# STM32WBA52 register map
File version: 0.1
CPU: CM33 r0p1, little endian, MPU, FPU, 4 interrupt priority bits
Registers are 32-bit, read-write, reset 0x0 unless marked. A register's access mark holds for its fields unless they carry their own. Offsets are from the block's base; [hi:lo] are bit positions; {n}, {i} and the like mark numbered series.

## SAES — Secure AES coprocessor
Base 0x420C0C00
Same registers: SEC_SAES 0x520C0C00
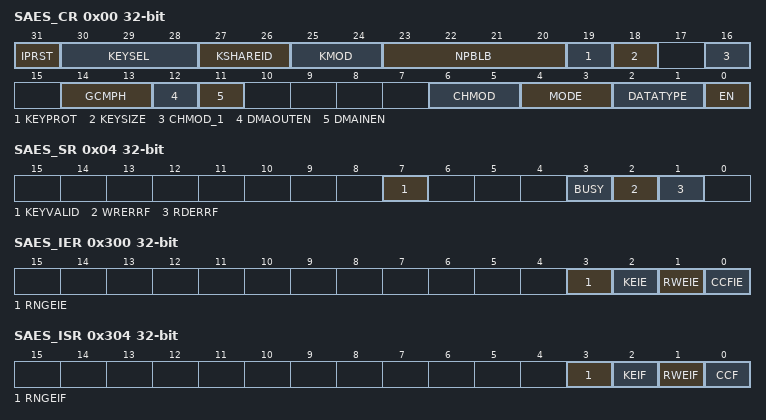
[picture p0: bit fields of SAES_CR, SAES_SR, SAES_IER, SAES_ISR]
0x00 SAES_CR — SAES control register
  [31] IPRST — SAES peripheral software reset Setting the bit resets the SAES peripheral, putting all registers to their default values, except the IPRST bit itself. Hence, any key-relative data are lost. For this reason, it is recommended to set the bit before handing over the SAES to a less secure application. The bit must be low while writing any configuration registers.
  [30:28] KEYSEL — Key selection The bitfield defines the source of the key information to use in the AES cryptographic core. Others: Reserved (if used, unfreeze SAES with IPRST) When KEYSEL[2:0] is different from zero, selected key value is available in key registers when BUSY bit is cleared and KEYVALID is set in the SAES_SR register. Otherwise, the key error flag KEIF is set. Repeated writing of KEYSEL[2:0] with the same non-zero value only triggers the loading of DHUK or BHK when KEYVALID�is cleared. When the application software changes the key selection by writing the KEYSEL[2:0] bitfield, the key registers are immediately erased and the KEYVALID flag cleared. At the end of the decryption process, if KMOD[1:0] is other than zero, KEYSEL[2:0] is cleared. With the bitfield value other than zero and KEYVALID set, the application cannot transfer the ownership of SAES with a loaded key to an application running in another security context (such as secure, non-secure). More specifically, when security of an access to any register does not match the information recorded by SAES, the KEIF flag is set. Attempts to write the bitfield are ignored when the BUSY flag of SAES_SR register is set, as well as when the EN bit of the SAES_CR register is set before the write access and it is not cleared by that write access.
    0=Software key, loaded in key registers SAES_KEYx; 1=Derived hardware unique key (DHUK); 2=Boot hardware key (BHK); 4=XOR of DHUK and BHK; 7=Test mode key (256-bit hardware constant 0xA5A5...A5A5)
  [27:26] KSHAREID — Key share identification This bitfield defines, at the end of a decryption process with KMOD[1:0] at 10 (shared key), which target can read the SAES key registers using a dedicated hardware bus. Others: Reserved Attempts to write the bitfield are ignored when BUSY is set, as well as when EN is set before the write access and it is not cleared by that write access.
    0=AES peripheral
  [25:24] KMOD — Key mode selection The bitfield defines how the SAES key can be used by the application. KEYSIZE must be correctly initialized when setting KMOD[1:0] different from zero. Others: Reserved With KMOD[1:0] other than zero, any attempt to configure the SAES peripheral for use by an application belonging to a different security domain (such as secure or non-secure) results in automatic key erasure and setting of the KEIF flag. Attempts to write the bitfield are ignored when BUSY is set, as well as when EN is set before the write access and it is not cleared by that write access.
    0=Normal key mode. Key registers are freely usable, no specific usage or protection applies to SAES_DINR and SAES_DOUTR registers.; 1=Wrapped key mode. Key loaded in key registers can only be used to encrypt or decrypt AES keys. Hence, when a decryption is selected, read-as-zero SAES_DOUTR register is automatically loaded into SAES key registers after a successful decryption process.; 2=Shared key mode. After a successful decryption process, SAES key registers are shared with the peripheral described in KSHAREID[1:0] bitfield. This sharing is valid only while KMOD[1:0] at 10 and KEYVALID=1. When a decryption is selected, read-as-zero SAES_DOUTR register is automatically loaded into SAES key registers after a successful decryption process.
  [23:20] NPBLB — Number of padding bytes in last block This padding information must be filled by software before processing the last block of GCM payload encryption or CCM payload decryption, otherwise authentication tag computation is incorrect. ...
    0=All bytes are valid (no padding); 1=Padding for the last LSB byte; 15=Padding for the 15 LSB bytes of last block
  [19] KEYPROT — Key protection When set, hardware-based key protection is enabled. Attempts to write the bit are ignored when BUSY is set, as well as when EN is set before the write access and it is not cleared by that write access.
    0=When KEYVALID is set and KEYSEL[2:0]�=�0 application can transfer the ownership of the SAES, with its loaded key, to an application running in another security context (such as non-secure, secure); 1=When KEYVALID is set, key error flag (KEIF) is set when an access to any registers is detected, this access having a security context (for example, secure, non-secure) that does not match the one of the application that loaded the key
  [18] KEYSIZE — Key size selection This bitfield defines the key length in bits of the key used by SAES. When KMOD[1:0] is at 01 or 10, KEYSIZE also defines the length of the key to encrypt or decrypt. Attempts to write the bit are ignored when BUSY is set, as well as when the EN is set before the write access and it is not cleared by that write access.
    0=128-bit; 1=256-bit
  [16] CHMOD_1 — CHMOD[2]
  [14:13] GCMPH — GCM or CCM phase selection This bitfield selects the phase, applicable only with GCM, GMAC or CCM chaining modes. This bitfield has no effect if GCM, GMAC or CCM algorithm is not selected with CHMOD[2:0].
    0=Initialization phase; 1=Header phase; 2=Payload phase; 3=Final phase
  [12] DMAOUTEN — DMA output enable When this bit is set, DMA requests are automatically generated by the peripheral during the output data phase. Setting this bit is ignored when MODE[1:0] is at 01 (key derivation).
    0=DMA for outgoing data transfer is disabled; 1=DMA for outgoing data transfer is enabled
  [11] DMAINEN — DMA input enable When this bit is set, DMA requests are automatically generated by the peripheral during the input data phase. Setting this bit is ignored when MODE[1:0] is at 01 (key derivation).
    0=DMA for incoming data transfer is disabled; 1=DMA for incoming data transfer is enabled
  [6:5] CHMOD — CHMOD[1:0]: Chaining mode This bitfield selects the AES chaining mode: others: Reserved Attempts to write the bitfield are ignored when BUSY is set, as well as when EN is set before the write access and it is not cleared by that write access.
    0=Electronic codebook (ECB); 1=Cipher-block chaining (CBC); 2=Counter mode (CTR); 3=Galois counter mode (GCM) and Galois message authentication code (GMAC); 4=Counter with CBC-MAC (CCM)
  [4:3] MODE — Operating mode This bitfield selects the SAES operating mode: Attempts to write the bitfield are ignored when BUSY is set, as well as when EN is set before the write access and it is not cleared by that write access.
    0=Encryption; 1=Key derivation (or key preparation), for ECB/CBC decryption only; 2=Decryption
  [2:1] DATATYPE — Data type This bitfield defines the format of data written in the SAES_DINR register or read from the SAES_DOUTR register, through selecting the mode of data swapping. This swapping is defined in Section�23.4.17: SAES data registers and data swapping. Attempts to write the bitfield are ignored when BUSY is set, as well as when EN is set before the write access and it is not cleared by that write access.
    0=No swapping (32-bit data); 1=Half-word swapping (16-bit data); 2=Byte swapping (8-bit data); 3=Bit-level swapping
  [0] EN — Enable This bit enables/disables the SAES peripheral. At any moment, clearing then setting the bit re-initializes the SAES peripheral. When KMOD[1:0] is different from 00, using IPRST bit is recommended instead. This bit is automatically cleared by hardware upon the completion of the key preparation (MODE[1:0] at 01) and upon the completion of GCM/GMAC/CCM initialization phase. The bit cannot be set as long as KEYVALID�=�0. The situation is similar for one of the following configurations: 1. KMOD[1:0] at 01 (wrap), CHMOD[2:0] at 11 (GCM) 2. KMOD[1:0] at 01 (wrap), CHMOD[2:0] at 10 (CTR), MODE[1:0] at 00 (encryption).
    0=Disable; 1=Enable
0x04 SAES_SR ro — SAES status register
  [7] KEYVALID — Key valid flag This bit is set by hardware when the key of size defined by KEYSIZE is loaded in SAES_KEYRx key registers. The EN bit can only be set when KEYVALID is set. In normal mode when KEYSEL[2:0] is at 000, the key must be written in the key registers in the correct sequence, otherwise the KEIF flag is set and KEYVALID remains cleared. When KEYSEL[2:0] is different from zero, the BUSY flag is automatically set by SAES. When the key is loaded successfully, BUSY is cleared and KEYVALID set. Upon an error, KEIF is set, BUSY cleared and KEYVALID remains cleared. If set, KEIF must be cleared through the SAES_ICR register, otherwise KEYVALID cannot be set. See the KEIF flag description for more details. For further information on key loading, refer to Section�23.4.18: SAES key registers.
    0=Key not valid; 1=Key valid
  [3] BUSY — Busy This flag indicates whether SAES is idle or busy. SAES is flagged as idle when disabled or when the last processing is completed. SAES is flagged as busy when processing a block data, preparing a key (ECB or CBC decryption only), fetching random number from the RNG, or transferring a shared key to target peripheral. When GCM encryption is selected, this flag must be at zero before suspending current process to manage a higher-priority message. BUSY must also be cleared before selecting the GCM final phase.
    0=Idle; 1=Busy
  [2] WRERRF — Write error flag This bit is set when an unexpected write to the SAES_DINR register occurred. When set WRERRF bit has no impact on the SAES operations. This flag is cleared by setting the RWEIF bit in SAES_ICR register. If RWEIE bit is set in SAES_IER register an interrupt is generated when WRERRF is set. It is cleared by setting the RWEIF bit of the SAES_ICR register.
    0=No error; 1=Unexpected write to SAES_DINR register occurred during computation or data output phase
  [1] RDERRF — Read error flag This bit is set when an unexpected read to the SAES_DOUTR register occurred. When set RDERRF bit has no impact on the SAES operations. This flag is cleared by setting the RWEIF bit in SAES_ICR register. If RWEIE bit is set in SAES_IER register an interrupt is generated when RDERRF is set. It is cleared by setting the RWEIF bit of the SAES_ICR register.
    0=No error; 1=Unexpected read to SAES_DOUTR register occurred during computation or data input phase
0x08 SAES_DINR wo — SAES data input register
  [31:0] DIN — Input data word A four-fold sequential write to this bitfield during the Input phase results in writing a complete 16-bytes block of input data to the SAES peripheral. From the first to the fourth write, the corresponding data weights are [127:96], [95:64], [63:32], and [31:0]. Upon each write, the data from the 32-bit input buffer are handled by the data swap block according to the DATATYPE[1:0] bitfield, then written into the AES core 16-bytes input buffer. Reads return zero.
0x0C SAES_DOUTR ro — SAES data output register
  [31:0] DOUT — Output data word This read-only bitfield fetches a 32-bit output buffer. A four-fold sequential read of this bitfield, upon the computation completion (CCF flag set), virtually reads a complete 16-byte block of output data from the SAES peripheral. Before reaching the output buffer, the data produced by the AES core are handled by the data swap block according to the DATATYPE[1:0] bitfield. Data weights from the first to the fourth read operation are: [127:96], [95:64], [63:32], and [31:0].
0x10 SAES_KEYR0 wo — SAES key register 0
  [31:0] KEY — Cryptographic key, bits [31:0] This write-only bitfield contains the bits [31:0] of the AES encryption or decryption key, depending on the operating mode MODE[1:0] in SAES_CR. The SAES_KEYRx registers may be written only when KEYSIZE value is correct and when the SAES peripheral is disabled (EN bit of the SAES_CR register cleared). A special writing sequence is also required, as described in KEYVALID bit of the SAES_SR register. Note that, if KEYSEL[2:0] is different from 0 and KEYVALID�=�0, the key is directly loaded to SAES_KEYRx registers (hence writes to key register is ignored and KEIF is set). When KEYVALID is set a write to this register clears KEYVALID if SAES is disabled.
{0x10+4i} SAES_KEYR{i} wo (i=1..3) — SAES key register {i}
  [31:0] KEY — Cryptographic key, bits [{32i+31}:{32i}] Refer to the SAES_KEYR0 register for description of the KEY[255:0] bitfield. When KEYVALID is set in SAES_SR a write to this register clears KEYVALID if EN is cleared in SAES_CR.
0x20 SAES_IVR0 — SAES initialization vector register 0
  [31:0] IVI — Initialization vector input, bits [31:0] SAES_IVRx registers store the 128-bit initialization vector or the nonce, depending on the chaining mode selected. This value is updated by the AES core after each computation round (when applicable). Write to this register is ignored when EN bit is set in SAES_SR register
{0x20+4i} SAES_IVR{i} (i=1..3) — SAES initialization vector register {i}
  [31:0] IVI — Initialization vector input, bits [{32i+31}:{32i}] Refer to the SAES_IVR0 register for description of the IVI[128:0] bitfield.
{0x20+4i} SAES_KEYR{i} wo (i=4..7) — SAES key register {i}
  [31:0] KEY — Cryptographic key, bits [{32i+31}:{32i}] Refer to the SAES_KEYR0 register for description of the KEY[255:0] bitfield. Writing to this register has no effect when key size is 128-bit (KEYSIZE=0). When KEYVALID is set in SAES_SR a write to this register clears KEYVALID if EN is cleared in SAES_CR.
{0x40+4i} SAES_SUSPR{i} (i=0..7) — SAES suspend registers
  [31:0] SUSP — Suspend data SAES_SUSPRx registers contain the complete internal register states of the SAES when the CCM processing of the current task is suspended to process a higher-priority task. Refer to Section�23.4.8: SAES suspend and resume operations for more details. Read to this register returns zero when EN bit is cleared in SAES_SR register. SAES_SUSPRx registers are not used in other chaining modes than CCM.
0x300 SAES_IER — SAES interrupt enable register
  [all] fields
    0=Disabled (masked); 1=Enabled (not masked)
  [3] RNGEIE — RNG error interrupt enable This bit enables or disables (masks) the SAES interrupt generation when RNGEIF (RNG error flag) is set.
  [2] KEIE — Key error interrupt enable This bit enables or disables (masks) the SAES interrupt generation when KEIF (key error flag) is set.
  [1] RWEIE — Read or write error interrupt enable This bit enables or disables (masks) the SAES interrupt generation when RWEIF (read and/or write error flag) is set.
  [0] CCFIE — Computation complete flag interrupt enable This bit enables or disables (masks) the SAES interrupt generation when CCF (computation complete flag) is set.
0x304 SAES_ISR ro — SAES interrupt status register
  [3] RNGEIF — RNG error interrupt flag This read-only bit is set by hardware when an error is detected on RNG bus interface (e.g. bad entropy). RNGEIE bit is cleared when application sets the corresponding bit of SAES_ICR register. An interrupt is generated if the RNGEIE bit has been previously set in the SAES_IER register. Clearing this bit triggers the reload of a new random number from RNG peripheral.
    0=RNG bus is functional; 1=Error detected on RNG bus interface (random seed fetching error)
  [2] KEIF — Key error interrupt flag This read-only bit is set by hardware when key information failed to load into key registers or key register usage is forbidden. Setting the corresponding bit of the SAES_ICR register clears the KEIF and generates interrupt if the KEIE bit of the SAES_IER register is set. KEIF is triggered upon any of the following errors: SAES fails to load the DHUK (KEYSEL[2:0]�=�001 or 100). SAES fails to load the BHK (KEYSEL[2:0]�=�010 or 100) respecting the correct order. AES fails to load the key shared by SAES peripheral (KMOD�=�10). When KEYVALID is set and either KEYPROT is set or KEYSEL[2:0] is other than 000, the security context of the application that loads the key (secure or non-secure) does not match the security attribute of the access to SAES_CR or SAES_DOUT. In this case, KEYVALID and EN bits are cleared. SAES_KEYRx register write does not respect the correct order. (For KEYSIZE�=�0, SAES_KEYR0 then SAES_KEYR1 then SAES_KEYR2 then SAES_KEYR3 register, or reverse. For KEYSIZE set, SAES_KEYR0 then SAES_KEYR1 then SAES_KEYR2 then SAES_KEYR3 then SAES_KEYR4 then SAES_KEYR5 then SAES_KEYR6 then SAES_KEYR7, or reverse). KEIF must be cleared by the application software, otherwise KEYVALID cannot be set.
    0=No key error detected; 1=Key information failed to load into key registers, or key register use is forbidden
  [1] RWEIF — Read or write error interrupt flag This read-only bit is set by hardware when a RDERRF or a WRERRF error flag is set in the SAES_SR register. RWEIF bit is cleared when application sets the corresponding bit of SAES_ICR register. An interrupt is generated if the RWEIE bit has been previously set in the SAES_IER register. This flags has no meaning when key derivation mode is selected.
    0=No read or write error detected; 1=Read or write error detected (see SAES_SR register for details)
  [0] CCF — Computation complete flag This flag indicates whether the computation is completed. It is significant only when the DMAOUTEN bit is cleared, and it may stay high when DMAOUTEN is set. CCF bit is cleared when application sets the corresponding bit of AES_ICR register. An interrupt is generated if the CCFIE bit has been previously set in the AES_IER register.
    0=Not completed; 1=Completed
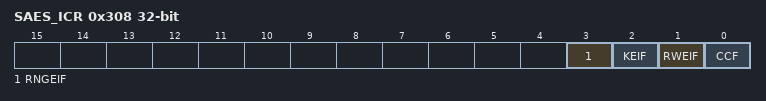
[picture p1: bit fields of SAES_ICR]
0x308 SAES_ICR wo — SAES interrupt clear register
  [3] RNGEIF — RNG error interrupt flag clear Application must set this bit to clear the RNGEIF status bit in SAES_ISR register.
  [2] KEIF — Key error interrupt flag clear Setting this bit clears the KEIF status bit of the SAES_ISR register.
  [1] RWEIF — Read or write error interrupt flag clear Setting this bit clears the RWEIF status bit of the SAES_ISR register, and clears both RDERRF and WRERRF flags in the SAES_SR register.
  [0] CCF — Computation complete flag clear Setting this bit clears the CCF status bit of the SAES_ISR register.
